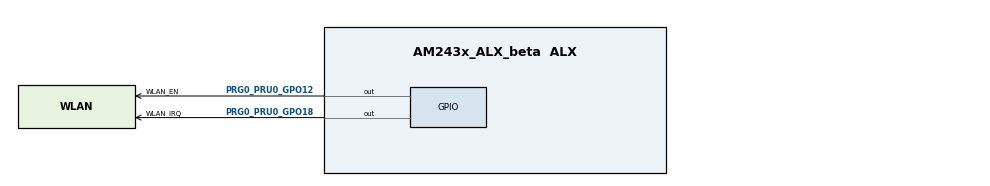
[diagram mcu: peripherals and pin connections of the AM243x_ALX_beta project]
/**
 * @cliArgs --device "AM243x_ALX_beta" --package "ALX" --part "ALX" --context "r5fss0-0" --product "MCU_PLUS_SDK_AM243x@08.05.00"
 * @versions {"tool":"1.19.0+3427"}
 */

/**
 * Import the modules used in this configuration.
 */
const flash      = scripting.addModule("/board/flash/flash", {}, false);
const flash1     = flash.addInstance();
const gpio       = scripting.addModule("/drivers/gpio/gpio", {}, false);
const gpio1      = gpio.addInstance();
const gpio2      = gpio.addInstance();
const mcspi      = scripting.addModule("/drivers/mcspi/mcspi", {}, false);
const mcspi1     = mcspi.addInstance();
const uart       = scripting.addModule("/drivers/uart/uart", {}, false);
const uart1      = uart.addInstance();
const debug_log  = scripting.addModule("/kernel/dpl/debug_log");
const mpu_armv7  = scripting.addModule("/kernel/dpl/mpu_armv7", {}, false);
const mpu_armv71 = mpu_armv7.addInstance();
const mpu_armv72 = mpu_armv7.addInstance();
const mpu_armv73 = mpu_armv7.addInstance();
const mpu_armv74 = mpu_armv7.addInstance();
const mpu_armv75 = mpu_armv7.addInstance();
const mpu_armv76 = mpu_armv7.addInstance();
const mpu_armv77 = mpu_armv7.addInstance();

/**
 * Write custom configuration values to the imported modules.
 */
flash1.$name                         = "CONFIG_FLASH0";
flash1.peripheralDriver.$name        = "CONFIG_OSPI0";
flash1.peripheralDriver.inputClkFreq = 50000000;
flash1.peripheralDriver.dmaEnable    = true;

gpio1.$name                = "WLAN_EN";
gpio1.pinDir               = "OUTPUT";
gpio1.GPIO.gpioPin.$assign = "PRG0_PRU0_GPO12";

gpio2.$name                = "WLAN_IRQ";
gpio2.trigType             = "RISE_EDGE";
gpio2.intrOut              = "9";
gpio2.GPIO.$assign         = "GPIO1";
gpio2.GPIO.gpioPin.$assign = "PRG0_PRU0_GPO18";

mcspi1.$name                    = "CONFIG_MCSPI0";
mcspi1.SPI.$assign              = "SPI3";
mcspi1.mcspiChannel[0].$name    = "CONFIG_MCSPI_CH1";
mcspi1.mcspiChannel[0].bitRate  = 20000000;
mcspi1.mcspiChannel[0].advanced = true;

uart1.$name        = "CONFIG_UART_BLE";
uart1.rxTrigLvl    = "1";
uart1.baudRate     = 9600;
uart1.UART.$assign = "USART2";

const udma                         = scripting.addModule("/drivers/udma/udma", {}, false);
const udma1                        = udma.addInstance({}, false);
udma1.$name                        = "CONFIG_UDMA0";
flash1.peripheralDriver.udmaDriver = udma1;

debug_log.enableUartLog        = true;
debug_log.uartLog.$name        = "CONFIG_UART_CONSOLE";
debug_log.uartLog.rxTrigLvl    = "1";
debug_log.uartLog.UART.$assign = "USART0";

mpu_armv71.$name             = "CONFIG_MPU_REGION0";
mpu_armv71.size              = 31;
mpu_armv71.attributes        = "Device";
mpu_armv71.accessPermissions = "Supervisor RD+WR, User RD";
mpu_armv71.allowExecute      = false;

mpu_armv72.$name             = "CONFIG_MPU_REGION1";
mpu_armv72.size              = 15;
mpu_armv72.accessPermissions = "Supervisor RD+WR, User RD";

mpu_armv73.$name             = "CONFIG_MPU_REGION2";
mpu_armv73.baseAddr          = 0x41010000;
mpu_armv73.size              = 15;
mpu_armv73.accessPermissions = "Supervisor RD+WR, User RD";

mpu_armv74.$name             = "CONFIG_MPU_REGION3";
mpu_armv74.baseAddr          = 0x70000000;
mpu_armv74.size              = 21;
mpu_armv74.accessPermissions = "Supervisor RD+WR, User RD";

mpu_armv75.$name             = "CONFIG_MPU_REGION4";
mpu_armv75.baseAddr          = 0x60000000;
mpu_armv75.size              = 28;
mpu_armv75.accessPermissions = "Supervisor RD, User RD";

mpu_armv76.$name       = "CONFIG_MPU_REGION5";
mpu_armv76.size        = 17;
mpu_armv76.baseAddr    = 0x4B00000;
mpu_armv76.attributes  = "CUSTOM";
mpu_armv76.tex         = 0;
mpu_armv76.isCacheable = false;

mpu_armv77.$name       = "CONFIG_MPU_REGION6";
mpu_armv77.baseAddr    = 0x20100000;
mpu_armv77.size        = 18;
mpu_armv77.attributes  = "CUSTOM";
mpu_armv77.tex         = 0;
mpu_armv77.isCacheable = false;

/**
 * Pinmux solution for unlocked pins/peripherals. This ensures that minor changes to the automatic solver in a future
 * version of the tool will not impact the pinmux you originally saw.  These lines can be completely deleted in order to
 * re-solve from scratch.
 */
flash1.peripheralDriver.OSPI.$suggestSolution      = "OSPI0";
flash1.peripheralDriver.OSPI.CLK.$suggestSolution  = "OSPI0_CLK";
flash1.peripheralDriver.OSPI.CSn0.$suggestSolution = "OSPI0_CSn0";
flash1.peripheralDriver.OSPI.D3.$suggestSolution   = "OSPI0_D3";
flash1.peripheralDriver.OSPI.D2.$suggestSolution   = "OSPI0_D2";
flash1.peripheralDriver.OSPI.D1.$suggestSolution   = "OSPI0_D1";
flash1.peripheralDriver.OSPI.D0.$suggestSolution   = "OSPI0_D0";
gpio1.GPIO.$suggestSolution                        = "GPIO1";
mcspi1.SPI.CLK.$suggestSolution                    = "PRG0_PRU0_GPO16";
mcspi1.SPI.D0.$suggestSolution                     = "PRG0_PRU0_GPO13";
mcspi1.SPI.D1.$suggestSolution                     = "PRG0_PRU0_GPO14";
mcspi1.mcspiChannel[0].CSn.$suggestSolution        = "PRG0_PRU0_GPO17";
uart1.UART.RXD.$suggestSolution                    = "GPMC0_AD0";
uart1.UART.TXD.$suggestSolution                    = "GPMC0_AD1";
debug_log.uartLog.UART.RXD.$suggestSolution        = "UART0_RXD";
debug_log.uartLog.UART.TXD.$suggestSolution        = "UART0_TXD";
